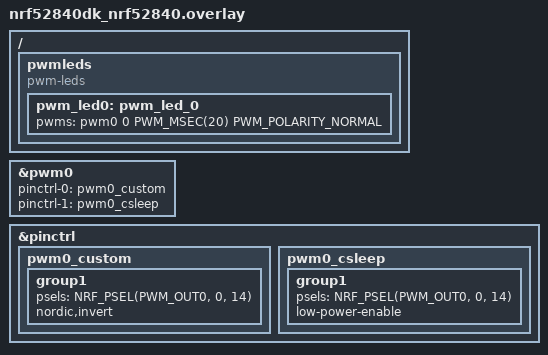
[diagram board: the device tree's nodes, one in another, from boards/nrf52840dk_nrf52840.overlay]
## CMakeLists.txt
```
cmake_minimum_required(VERSION 3.20.0)
find_package(Zephyr REQUIRED HINTS $ENV{ZEPHYR_BASE})

project(zephyr_pwm_demo)

target_sources(app PRIVATE src/main.c)
```

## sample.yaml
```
sample:
  description: nRF Connect SDK Intermediate Course by Nordic Developer Academy.
  name: Pulse Width Modulated LED brightness control.
```

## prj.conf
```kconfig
# Enable Logging.
CONFIG_LOG=y
CONFIG_RTT_CONSOLE=y
CONFIG_LOG_BACKEND_UART=n
CONFIG_LOG_BACKEND_RTT=y

# Enable PWM.
CONFIG_PWM=y
CONFIG_PWM_LOG_LEVEL_DBG=n

# Enable LED and LED PWM.
CONFIG_LED=y
CONFIG_LED_PWM=y
```

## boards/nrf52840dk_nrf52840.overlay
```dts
/* 1. Add a pwm_led instance and change the polarity. */
/{
    pwmleds {
        compatible = "pwm-leds";
        pwm_led0: pwm_led_0 {
            pwms = <&pwm0 0 PWM_MSEC(20) PWM_POLARITY_NORMAL>;
        };
    };
};

/* 2. Add your own custom pwm0 instance. */
&pwm0 {
    status = "okay";
    pinctrl-0 = <&pwm0_custom>;
    pinctrl-1 = <&pwm0_csleep>;
    pinctrl-names = "default", "sleep";
};

/* 3. Configure which pins your custom pwm0 instance should use. */
&pinctrl {
    pwm0_custom: pwm0_custom {
        group1 {
            psels = <NRF_PSEL(PWM_OUT0, 0, 14)>;
            nordic,invert;
        };
    };

    pwm0_csleep: pwm0_csleep {
        group1 {
            psels = <NRF_PSEL(PWM_OUT0, 0, 14)>;
            low-power-enable;
        };
    };
};
```

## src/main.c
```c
#include <inttypes.h>
#include <zephyr/kernel.h>

/* 1. Include the relevant headers for pwm. */
#include <zephyr/device.h>
#include <zephyr/drivers/pwm.h>

#include <zephyr/logging/log.h>
LOG_MODULE_REGISTER(Lesson4_Exercise1, LOG_LEVEL_INF);

/* 2. Define fading parameters. */
#define NUM_STEPS   50U
#define SLEEP_MSEC  25U

/* 3a. Get the node identifier for [] through its alias. */
#define PWM_LED0     DT_ALIAS(pwm_led0)

/* 3b. Initialize and populate struct pwm_dt_spec. */
static const struct pwm_dt_spec pwm_led0 = PWM_DT_SPEC_GET(PWM_LED0);

int main(void)
{
    int err = 0;
    uint32_t pulse_width = 0U;
    uint32_t step = pwm_led0.period / NUM_STEPS;
    bool fading = false;

    /* 4. Check if the device is ready. */
    if (!pwm_is_ready_dt(&pwm_led0)) {
        LOG_ERR("Error: PWM device %s is not ready", pwm_led0.dev->name);
        return 0;
	}

    /* Once started, the PWM signal will be generated by the PWM peripheral
       within the SoC independent of the CPU - meaning you can use the CPU
       to do other work in parallel. */
    for (;;) {
		err = pwm_set_pulse_dt(&pwm_led0, pulse_width);
		if (err) {
			LOG_ERR("%d: failed to set pulse width\n", err);
			return 0;
		}
		if (!fading) {
			pulse_width += step;
			if (pulse_width >= pwm_led0.period) {
				pulse_width = pwm_led0.period - step;
				fading = true;
			}
		} else {
			if (pulse_width >= step) {
				pulse_width -= step;
			} else {
				pulse_width = step;
				fading = false;
			}
		}
		k_sleep(K_MSEC(SLEEP_MSEC));
    }
    
    return 0;
}
```
